VERSION ""

NS_ :

BS_:

BU_: VCU AUTO

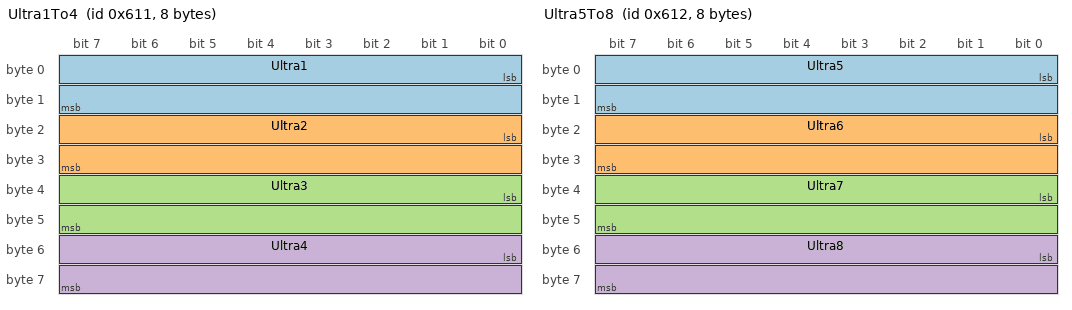
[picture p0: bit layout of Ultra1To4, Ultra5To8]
BO_ 1553 Ultra1To4: 8 VCU
 SG_ Ultra1 : 0|16@1+ (1,0) [0|5000] "mm"  AUTO
 SG_ Ultra2 : 16|16@1+ (1,0) [0|5000] "mm"  AUTO
 SG_ Ultra3 : 32|16@1+ (1,0) [0|5000] "mm"  AUTO
 SG_ Ultra4 : 48|16@1+ (1,0) [0|5000] "mm"  AUTO

BO_ 1554 Ultra5To8: 8 VCU
 SG_ Ultra5 : 0|16@1+ (1,0) [0|5000] "mm"  AUTO
 SG_ Ultra6 : 16|16@1+ (1,0) [0|5000] "mm"  AUTO
 SG_ Ultra7 : 32|16@1+ (1,0) [0|5000] "mm"  AUTO
 SG_ Ultra8 : 48|16@1+ (1,0) [0|5000] "mm"  AUTO

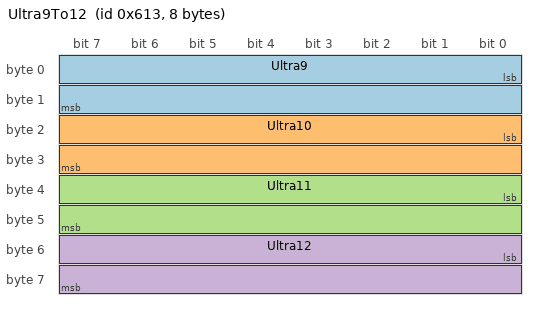
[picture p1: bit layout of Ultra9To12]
BO_ 1555 Ultra9To12: 8 VCU
 SG_ Ultra9  : 0|16@1+ (1,0) [0|5000] "mm"  AUTO
 SG_ Ultra10 : 16|16@1+ (1,0) [0|5000] "mm"  AUTO
 SG_ Ultra11 : 32|16@1+ (1,0) [0|5000] "mm"  AUTO
 SG_ Ultra12 : 48|16@1+ (1,0) [0|5000] "mm"  AUTO

CM_ SG_ 1553 Ultra1 "号探头超声波距离值";
CM_ SG_ 1553 Ultra2 "号探头超声波距离值";
CM_ SG_ 1553 Ultra3 "号探头超声波距离值";
CM_ SG_ 1553 Ultra4 "号探头超声波距离值";

CM_ SG_ 1554 Ultra5 "号探头超声波距离值";
CM_ SG_ 1554 Ultra6 "号探头超声波距离值";
CM_ SG_ 1554 Ultra7 "号探头超声波距离值";
CM_ SG_ 1554 Ultra8 "号探头超声波距离值";

CM_ SG_ 1555 Ultra9 "号探头超声波距离值";
CM_ SG_ 1555 Ultra10 "号探头超声波距离值";
CM_ SG_ 1555 Ultra11 "号探头超声波距离值";
CM_ SG_ 1555 Ultra12 "号探头超声波距离值";
